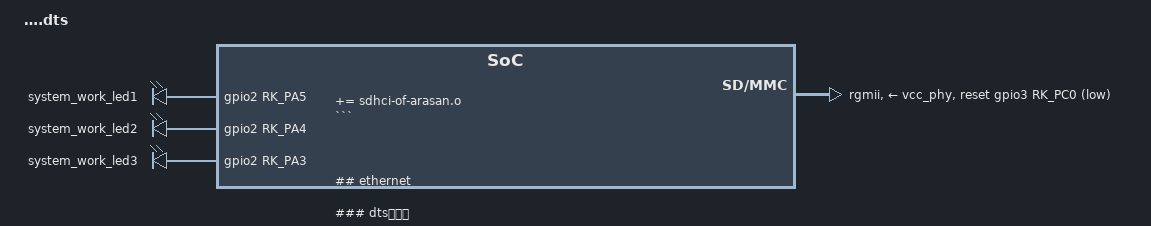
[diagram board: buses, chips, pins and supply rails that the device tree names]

## emmc

### 硬件电路

### dts设备树


```shell
sdhci: sdhci@fe330000 {
		compatible = "rockchip,rk3399-sdhci-5.1", "arasan,sdhci-5.1";
		reg = <0x0 0xfe330000 0x0 0x10000>;
		interrupts = <GIC_SPI 11 IRQ_TYPE_LEVEL_HIGH 0>;
		arasan,soc-ctl-syscon = <&grf>;
		assigned-clocks = <&cru SCLK_EMMC>;
		assigned-clock-rates = <200000000>;
		clocks = <&cru SCLK_EMMC>, <&cru ACLK_EMMC>;
		clock-names = "clk_xin", "clk_ahb";
		clock-output-names = "emmc_cardclock";
		#clock-cells = <0>;
		phys = <&emmc_phy>;
		phy-names = "phy_arasan";
		power-domains = <&power RK3399_PD_EMMC>;
		status = "disabled";
	};
```

### 内核驱动

```shell
# rg rockchip,rk3399-sdhci-5.1

drivers/mmc/host/sdhci-of-arasan.c
1475:		.compatible = "rockchip,rk3399-sdhci-5.1",
1927:	if (of_device_is_compatible(np, "rockchip,rk3399-sdhci-5.1"))
```

因此需要打开 CONFIG_MMC_SDHCI_OF_ARASAN 配置，否则emmc无法识别

```shell
# grep sdhci-of-arasan drivers/mmc/host/Makefile
obj-$(CONFIG_MMC_SDHCI_OF_ARASAN)	+= sdhci-of-arasan.o
```



## ethernet

### dts设备树

```shell
&gmac {
	phy-supply = <&vcc_phy>;
	phy-mode = "rgmii";
	clock_in_out = "input";
	snps,reset-gpio = <&gpio3 RK_PC0 GPIO_ACTIVE_LOW>;
	snps,reset-active-low;
	snps,reset-delays-us = <0 10000 50000>;
	assigned-clocks = <&cru SCLK_RMII_SRC>;
	assigned-clock-parents = <&clkin_gmac>;
	pinctrl-names = "default";
	pinctrl-0 = <&rgmii_pins>;
	tx_delay = <0x28>;
	rx_delay = <0x20>;
	status = "okay";
};
```

### 内核驱动

```shell
# rg "rockchip,rk3399-gmac"

drivers/net/ethernet/stmicro/stmmac/dwmac-rk.c
2109:	{ .compatible = "rockchip,rk3399-gmac", .data = &rk3399_ops },
```

```shell
# grep -i dwmac-rk drivers/net/ethernet/stmicro/stmmac/Makefile 
obj-$(CONFIG_DWMAC_ROCKCHIP)	+= dwmac-rk.o
# 
# grep -i CONFIG_DWMAC_ROCKCHIP .config
CONFIG_DWMAC_ROCKCHIP=y
# 
```

必须配置 CONFIG_DWMAC_ROCKCHIP 否则缺失驱动


## led


### 硬件电路

### dts设备树

```shell
	leds: gpio-leds {
		compatible = "gpio-leds";
		pinctrl-names = "default";
		pinctrl-0 =<&leds_gpio>;

		led@1 {
			gpios = <&gpio2 RK_PA5 GPIO_ACTIVE_HIGH>;
			label = "system_work_led1"; // Blue LED
			retain-state-suspended;
		};

		led@2 {
			gpios = <&gpio2 RK_PA4 GPIO_ACTIVE_HIGH>;
			label = "system_work_led2"; // Red LED
			retain-state-suspended;
		};

		led@3 {
			gpios = <&gpio2 RK_PA3 GPIO_ACTIVE_HIGH>;
			label = "system_work_led3"; // Green LED
			retain-state-suspended;
		};
	};
```

### 内核驱动


## usb设备


## 电源管理

### 硬件电路

主 PMIC：U2100 = DRK809-3（即 RK809）
另有两颗 TCS452x（TI 的 DCDC）：
一颗供 VDD_CPU_B（大核 A72）
一颗供 VDD_GPU

### dts配置

```shell
regulator.0 -> ../../devices/platform/reg-dummy/regulator/regulator.0
regulator.1 -> ../../devices/platform/vcc-phy-regulator/regulator/regulator.1
regulator.10 -> ../../devices/platform/ff3c0000.i2c/i2c-0/0-0020/regulator/regulator.10
regulator.11 -> ../../devices/platform/ff3c0000.i2c/i2c-0/0-0020/regulator/regulator.11
regulator.12 -> ../../devices/platform/ff3c0000.i2c/i2c-0/0-0020/regulator/regulator.12
regulator.13 -> ../../devices/platform/ff3c0000.i2c/i2c-0/0-0020/regulator/regulator.13
regulator.14 -> ../../devices/platform/ff3c0000.i2c/i2c-0/0-0020/regulator/regulator.14
regulator.15 -> ../../devices/platform/ff3c0000.i2c/i2c-0/0-0020/regulator/regulator.15
regulator.16 -> ../../devices/platform/ff3c0000.i2c/i2c-0/0-0020/regulator/regulator.16
regulator.17 -> ../../devices/platform/ff3c0000.i2c/i2c-0/0-0020/regulator/regulator.17
regulator.18 -> ../../devices/platform/ff3c0000.i2c/i2c-0/0-0020/regulator/regulator.18
regulator.19 -> ../../devices/platform/ff3c0000.i2c/i2c-0/0-0020/regulator/regulator.19
regulator.2 -> ../../devices/platform/vccsys/regulator/regulator.2
regulator.20 -> ../../devices/platform/ff3c0000.i2c/i2c-0/0-0020/regulator/regulator.20
regulator.21 -> ../../devices/platform/ff3c0000.i2c/i2c-0/0-0020/regulator/regulator.21
regulator.22 -> ../../devices/platform/ff3c0000.i2c/i2c-0/0-001c/regulator/regulator.22
regulator.23 -> ../../devices/platform/ff3c0000.i2c/i2c-0/0-0010/regulator/regulator.23
regulator.3 -> ../../devices/platform/vdd_log/regulator/regulator.3
regulator.4 -> ../../devices/platform/vcc-4g-regulator/regulator/regulator.4
regulator.5 -> ../../devices/platform/vcc-pcie-regulator/regulator/regulator.5
regulator.6 -> ../../devices/platform/ff3c0000.i2c/i2c-0/0-0020/regulator/regulator.6
regulator.7 -> ../../devices/platform/ff3c0000.i2c/i2c-0/0-0020/regulator/regulator.7
regulator.8 -> ../../devices/platform/ff3c0000.i2c/i2c-0/0-0020/regulator/regulator.8
regulator.9 -> ../../devices/platform/ff3c0000.i2c/i2c-0/0-0020/regulator/regulator.9
```


### 驱动配置


## i2c配置
### 硬件电路


### dts配置

```shell
root@armbian:~# ls -alh /sys/bus/i2c/devices/
total 0
drwxr-xr-x 2 root root 0 Jan  1  1970 .
drwxr-xr-x 4 root root 0 Jan  1  1970 ..
lrwxrwxrwx 1 root root 0 Jan  1  1970 0-0010 -> ../../../devices/platform/ff3c0000.i2c/i2c-0/0-0010
lrwxrwxrwx 1 root root 0 Jan  1  1970 0-001c -> ../../../devices/platform/ff3c0000.i2c/i2c-0/0-001c
lrwxrwxrwx 1 root root 0 Jan  1  1970 0-0020 -> ../../../devices/platform/ff3c0000.i2c/i2c-0/0-0020
lrwxrwxrwx 1 root root 0 Jan  1  1970 6-0047 -> ../../../devices/platform/ff150000.i2c/i2c-6/6-0047
lrwxrwxrwx 1 root root 0 Jan  1  1970 7-0013 -> ../../../devices/platform/ff160000.i2c/i2c-7/7-0013
lrwxrwxrwx 1 root root 0 Jan  1  1970 8-0022 -> ../../../devices/platform/ff3e0000.i2c/i2c-8/8-0022
lrwxrwxrwx 1 root root 0 Jan  1  1970 i2c-0 -> ../../../devices/platform/ff3c0000.i2c/i2c-0
lrwxrwxrwx 1 root root 0 Jan  1  1970 i2c-1 -> ../../../devices/platform/ff110000.i2c/i2c-1
lrwxrwxrwx 1 root root 0 Jan  1  1970 i2c-2 -> ../../../devices/platform/ff120000.i2c/i2c-2
lrwxrwxrwx 1 root root 0 Jan  1  1970 i2c-3 -> ../../../devices/platform/ff130000.i2c/i2c-3
lrwxrwxrwx 1 root root 0 Jan  1  1970 i2c-4 -> ../../../devices/platform/ff3d0000.i2c/i2c-4
lrwxrwxrwx 1 root root 0 Jan  1  1970 i2c-6 -> ../../../devices/platform/ff150000.i2c/i2c-6
lrwxrwxrwx 1 root root 0 Jan  1  1970 i2c-7 -> ../../../devices/platform/ff160000.i2c/i2c-7
lrwxrwxrwx 1 root root 0 Jan  1  1970 i2c-8 -> ../../../devices/platform/ff3e0000.i2c/i2c-8
```

### 驱动配置



## usb配置


### 硬件电路


### dts配置
```shell
# ls /sys/bus/usb/devices/ -alh
total 0
drwxr-xr-x 2 root root 0 Jan 31 15:11 .
drwxr-xr-x 4 root root 0 Feb 20  2019 ..
lrwxrwxrwx 1 root root 0 Feb 20  2019 1-0:1.0 -> ../../../devices/platform/usb1/fe900000.dwc3/xhci-hcd.10.auto/usb1/1-0:1.0
lrwxrwxrwx 1 root root 0 Feb 20  2019 1-1 -> ../../../devices/platform/usb1/fe900000.dwc3/xhci-hcd.10.auto/usb1/1-1
lrwxrwxrwx 1 root root 0 Feb 20  2019 1-1:1.0 -> ../../../devices/platform/usb1/fe900000.dwc3/xhci-hcd.10.auto/usb1/1-1/1-1:1.0
lrwxrwxrwx 1 root root 0 Feb 20  2019 2-0:1.0 -> ../../../devices/platform/usb1/fe900000.dwc3/xhci-hcd.10.auto/usb2/2-0:1.0
lrwxrwxrwx 1 root root 0 Feb 20  2019 2-1 -> ../../../devices/platform/usb1/fe900000.dwc3/xhci-hcd.10.auto/usb2/2-1
lrwxrwxrwx 1 root root 0 Jan 31 07:34 2-1.1 -> ../../../devices/platform/usb1/fe900000.dwc3/xhci-hcd.10.auto/usb2/2-1/2-1.1
lrwxrwxrwx 1 root root 0 Jan 31 11:04 2-1.1:1.0 -> ../../../devices/platform/usb1/fe900000.dwc3/xhci-hcd.10.auto/usb2/2-1/2-1.1/2-1.1:1.0
lrwxrwxrwx 1 root root 0 Jan 31 11:04 2-1.1:1.1 -> ../../../devices/platform/usb1/fe900000.dwc3/xhci-hcd.10.auto/usb2/2-1/2-1.1/2-1.1:1.1
lrwxrwxrwx 1 root root 0 Feb 20  2019 2-1:1.0 -> ../../../devices/platform/usb1/fe900000.dwc3/xhci-hcd.10.auto/usb2/2-1/2-1:1.0
lrwxrwxrwx 1 root root 0 Feb 20  2019 3-0:1.0 -> ../../../devices/platform/fe380000.usb/usb3/3-0:1.0
lrwxrwxrwx 1 root root 0 Feb 20  2019 3-1 -> ../../../devices/platform/fe380000.usb/usb3/3-1
lrwxrwxrwx 1 root root 0 Feb 20  2019 3-1:1.0 -> ../../../devices/platform/fe380000.usb/usb3/3-1/3-1:1.0
lrwxrwxrwx 1 root root 0 Feb 20  2019 3-1:1.1 -> ../../../devices/platform/fe380000.usb/usb3/3-1/3-1:1.1
lrwxrwxrwx 1 root root 0 Feb 20  2019 3-1:1.2 -> ../../../devices/platform/fe380000.usb/usb3/3-1/3-1:1.2
lrwxrwxrwx 1 root root 0 Feb 20  2019 4-0:1.0 -> ../../../devices/platform/fe3c0000.usb/usb4/4-0:1.0
lrwxrwxrwx 1 root root 0 Feb 20  2019 5-0:1.0 -> ../../../devices/platform/fe3a0000.usb/usb5/5-0:1.0
lrwxrwxrwx 1 root root 0 Feb 20  2019 6-0:1.0 -> ../../../devices/platform/fe3e0000.usb/usb6/6-0:1.0
lrwxrwxrwx 1 root root 0 Feb 20  2019 usb1 -> ../../../devices/platform/usb1/fe900000.dwc3/xhci-hcd.10.auto/usb1
lrwxrwxrwx 1 root root 0 Feb 20  2019 usb2 -> ../../../devices/platform/usb1/fe900000.dwc3/xhci-hcd.10.auto/usb2
lrwxrwxrwx 1 root root 0 Feb 20  2019 usb3 -> ../../../devices/platform/fe380000.usb/usb3
lrwxrwxrwx 1 root root 0 Feb 20  2019 usb4 -> ../../../devices/platform/fe3c0000.usb/usb4
lrwxrwxrwx 1 root root 0 Feb 20  2019 usb5 -> ../../../devices/platform/fe3a0000.usb/usb5
lrwxrwxrwx 1 root root 0 Feb 20  2019 usb6 -> ../../../devices/platform/fe3e0000.usb/usb6
```

### 驱动配置


default rockchip-kernel-4.4
menu title Kdev U-Boot menu
prompt 1
timeout 90

label rockchip-kernel-4.4
	kernel /extlinux/Image
	fdt /extlinux/toybrick.dtb
	append  earlycon=uart8250,mmio32,0xff1a0000 initrd=/initramfs-toybrick-2.0.img root=PARTUUID=614e0000-0000-4b53-8000-1d28000054a9 rw rootwait rootfstype=ext4

label rockchip-kernel-6.6
	kernel /extlinux/Image-6.6
	fdt /extlinux/rk3399pro-toybrick-prod.dtb
	append  earlycon=uart8250,mmio32,0xff1a0000 console=ttyS2,1500000 rw rootwait rootfstype=ext4 initrd=/initrd.img-4.4.194 level=10 log_level=10 root=PARTUUID=614e0000-0000-4b53-8000-1d28000054a9


## xxx配置
### 硬件电路
### dts配置
### 驱动配置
